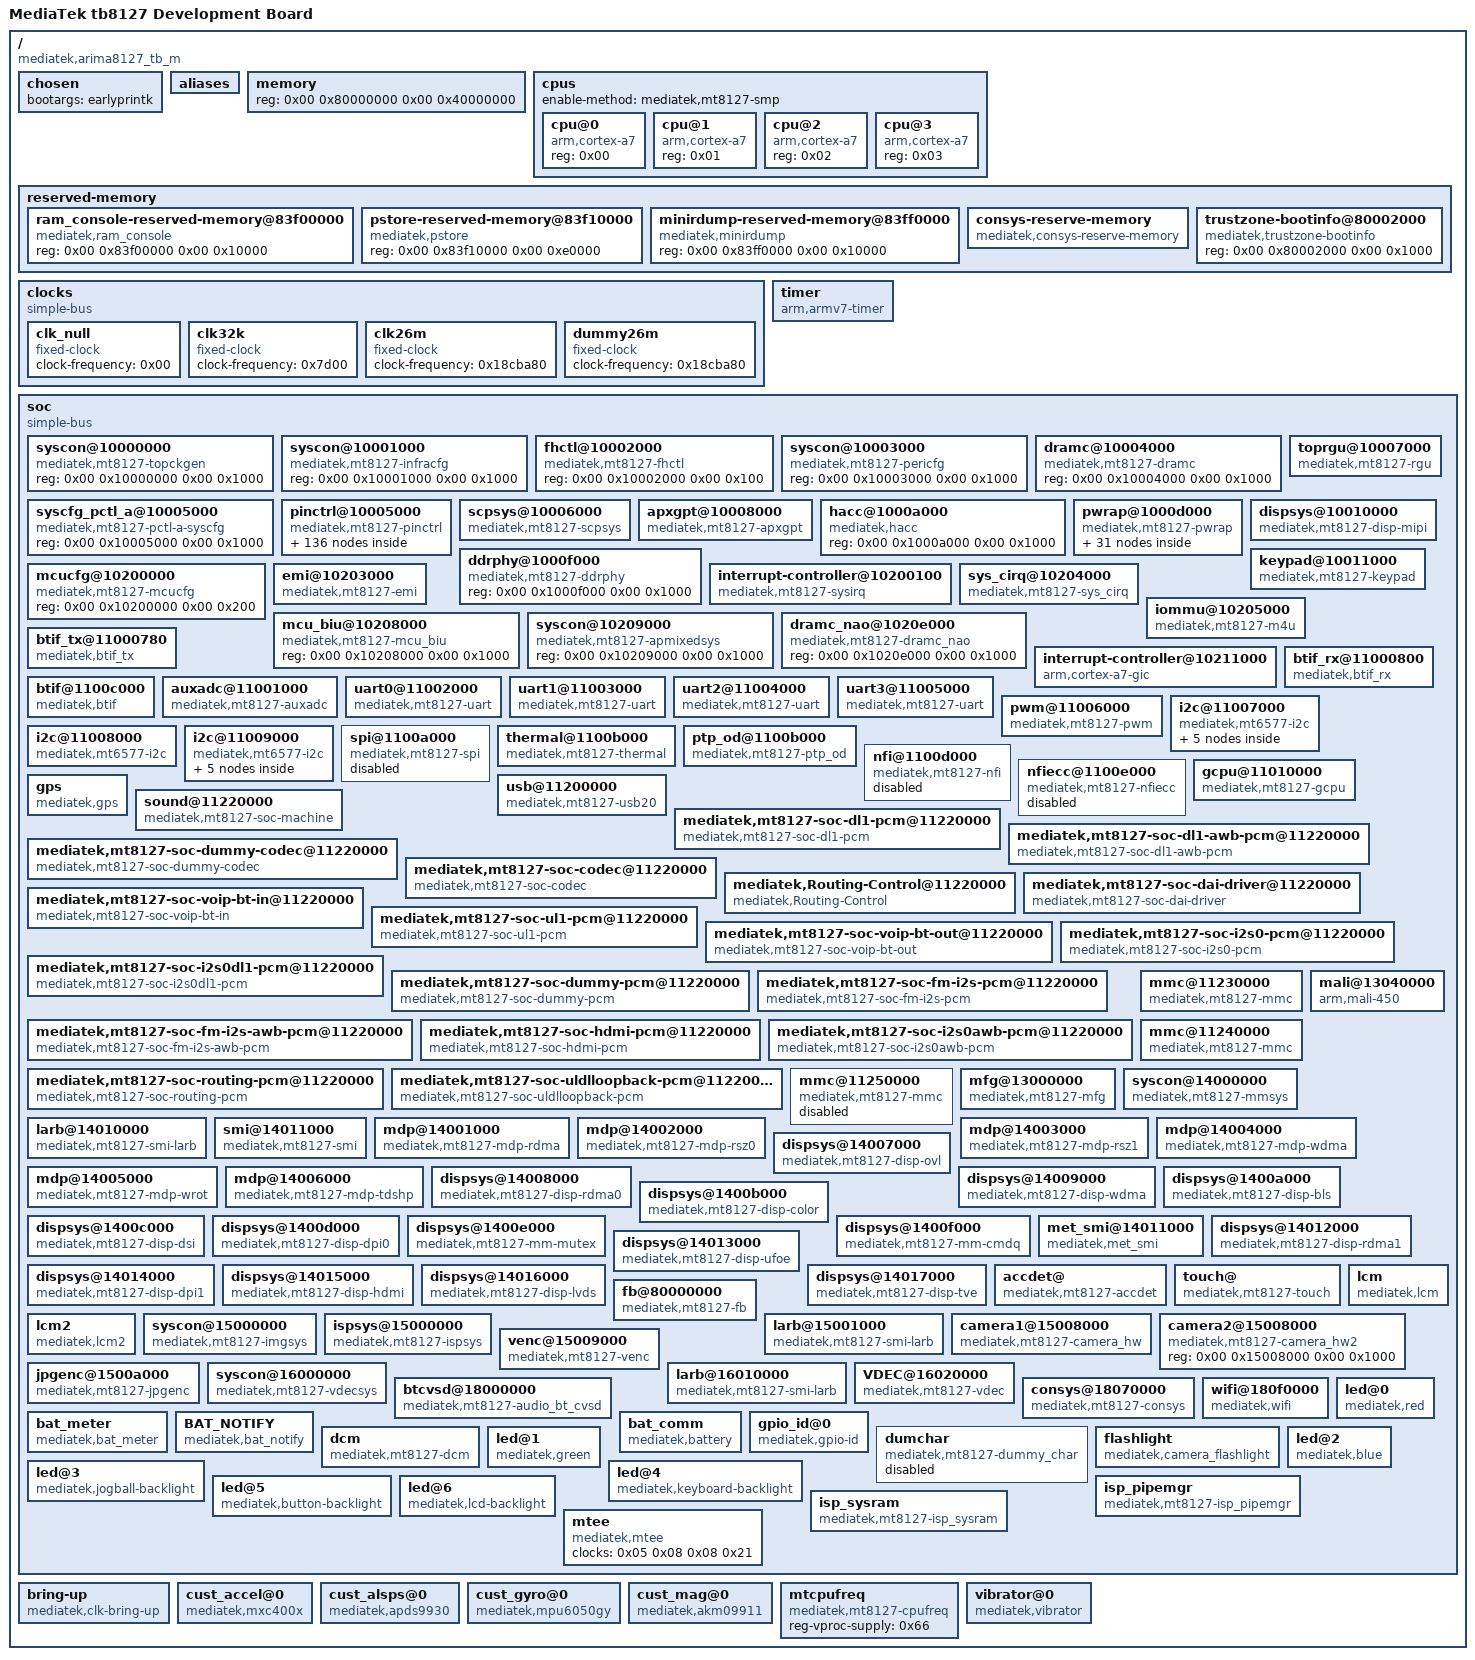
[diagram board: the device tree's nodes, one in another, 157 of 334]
/dts-v1/;

/ {
	#address-cells = <0x02>;
	#size-cells = <0x02>;
	compatible = "mediatek,arima8127_tb_m\0mediatek,mt8127";
	interrupt-parent = <0x01>;
	model = "MediaTek tb8127 Development Board";

	chosen {
		bootargs = "earlyprintk";
	};

	aliases {
	};

	memory {
		device_type = "memory";
		reg = <0x00 0x80000000 0x00 0x40000000>;
	};

	cpus {
		#address-cells = <0x01>;
		#size-cells = <0x00>;
		enable-method = "mediatek,mt8127-smp";

		cpu@0 {
			device_type = "cpu";
			compatible = "arm,cortex-a7";
			reg = <0x00>;
		};

		cpu@1 {
			device_type = "cpu";
			compatible = "arm,cortex-a7";
			reg = <0x01>;
		};

		cpu@2 {
			device_type = "cpu";
			compatible = "arm,cortex-a7";
			reg = <0x02>;
		};

		cpu@3 {
			device_type = "cpu";
			compatible = "arm,cortex-a7";
			reg = <0x03>;
		};
	};

	reserved-memory {
		#address-cells = <0x02>;
		#size-cells = <0x02>;
		ranges;

		ram_console-reserved-memory@83f00000 {
			compatible = "mediatek,ram_console";
			reg = <0x00 0x83f00000 0x00 0x10000>;
		};

		pstore-reserved-memory@83f10000 {
			compatible = "mediatek,pstore";
			reg = <0x00 0x83f10000 0x00 0xe0000>;
		};

		minirdump-reserved-memory@83ff0000 {
			compatible = "mediatek,minirdump";
			reg = <0x00 0x83ff0000 0x00 0x10000>;
		};

		consys-reserve-memory {
			compatible = "mediatek,consys-reserve-memory";
			no-map;
			size = <0x00 0x100000>;
			alignment = <0x00 0x100000>;
		};

		trustzone-bootinfo@80002000 {
			compatible = "mediatek,trustzone-bootinfo";
			reg = <0x00 0x80002000 0x00 0x1000>;
		};
	};

	clocks {
		#address-cells = <0x02>;
		#size-cells = <0x02>;
		compatible = "simple-bus";
		ranges;

		clk_null {
			compatible = "fixed-clock";
			#clock-cells = <0x00>;
			clock-frequency = <0x00>;
			linux,phandle = <0x28>;
			phandle = <0x28>;
		};

		clk32k {
			compatible = "fixed-clock";
			clock-frequency = <0x7d00>;
			#clock-cells = <0x00>;
		};

		clk26m {
			compatible = "fixed-clock";
			clock-frequency = <0x18cba80>;
			#clock-cells = <0x00>;
			linux,phandle = <0x27>;
			phandle = <0x27>;
		};

		dummy26m {
			compatible = "fixed-clock";
			clock-frequency = <0x18cba80>;
			#clock-cells = <0x00>;
		};
	};

	timer {
		compatible = "arm,armv7-timer";
		interrupt-parent = <0x02>;
		interrupts = <0x01 0x0d 0xf04 0x01 0x0e 0xf04 0x01 0x0b 0xf04 0x01 0x0a 0xf04>;
	};

	soc {
		#address-cells = <0x02>;
		#size-cells = <0x02>;
		compatible = "simple-bus";
		ranges;

		syscon@10000000 {
			compatible = "mediatek,mt8127-topckgen\0syscon";
			reg = <0x00 0x10000000 0x00 0x1000>;
			#clock-cells = <0x01>;
			linux,phandle = <0x06>;
			phandle = <0x06>;
		};

		syscon@10001000 {
			#address-cells = <0x01>;
			#size-cells = <0x01>;
			compatible = "mediatek,mt8127-infracfg\0syscon";
			reg = <0x00 0x10001000 0x00 0x1000>;
			#clock-cells = <0x01>;
			#reset-cells = <0x01>;
			linux,phandle = <0x05>;
			phandle = <0x05>;
		};

		fhctl@10002000 {
			compatible = "mediatek,mt8127-fhctl";
			reg = <0x00 0x10002000 0x00 0x100>;
		};

		syscon@10003000 {
			#address-cells = <0x01>;
			#size-cells = <0x01>;
			compatible = "mediatek,mt8127-pericfg\0syscon";
			reg = <0x00 0x10003000 0x00 0x1000>;
			#clock-cells = <0x01>;
			#reset-cells = <0x01>;
			linux,phandle = <0x08>;
			phandle = <0x08>;
		};

		dramc@10004000 {
			compatible = "mediatek,mt8127-dramc";
			reg = <0x00 0x10004000 0x00 0x1000>;
		};

		syscfg_pctl_a@10005000 {
			compatible = "mediatek,mt8127-pctl-a-syscfg\0syscon";
			reg = <0x00 0x10005000 0x00 0x1000>;
			linux,phandle = <0x03>;
			phandle = <0x03>;
		};

		pinctrl@10005000 {
			compatible = "mediatek,mt8127-pinctrl";
			reg = <0x00 0x1000b000 0x00 0x1000>;
			mediatek,pctl-regmap = <0x03>;
			pins-are-numbered;
			gpio-controller;
			#gpio-cells = <0x02>;
			interrupt-controller;
			#interrupt-cells = <0x02>;
			interrupts = <0x00 0x71 0x04 0x00 0x72 0x04>;
			pinctrl-names = "default";
			pinctrl-0 = <0x04>;
			linux,phandle = <0x07>;
			phandle = <0x07>;

			uart0gpiodefault {
				linux,phandle = <0x09>;
				phandle = <0x09>;
			};

			uart0_rx_set {
				linux,phandle = <0x0a>;
				phandle = <0x0a>;

				pins_cmd_dat {
					pinmux = <0x4f01>;
				};
			};

			uart0_rx_clear {
				linux,phandle = <0x0b>;
				phandle = <0x0b>;

				pins_cmd_dat {
					pinmux = <0x4f00>;
					slew-rate = <0x01>;
					output-high;
				};
			};

			uart0_tx_set {
				linux,phandle = <0x0c>;
				phandle = <0x0c>;

				pins_cmd_dat {
					pinmux = <0x5001>;
				};
			};

			uart0_tx_clear {
				linux,phandle = <0x0d>;
				phandle = <0x0d>;

				pins_cmd_dat {
					pinmux = <0x5000>;
					slew-rate = <0x01>;
					output-high;
				};
			};

			uart1gpiodefault {
				linux,phandle = <0x0e>;
				phandle = <0x0e>;
			};

			uart1_rx_set {
				linux,phandle = <0x0f>;
				phandle = <0x0f>;

				pins_cmd_dat {
					pinmux = <0x5101>;
				};
			};

			uart1_rx_clear {
				linux,phandle = <0x10>;
				phandle = <0x10>;

				pins_cmd_dat {
					pinmux = <0x5100>;
					slew-rate = <0x01>;
					output-high;
				};
			};

			uart1_tx_set {
				linux,phandle = <0x11>;
				phandle = <0x11>;

				pins_cmd_dat {
					pinmux = <0x5201>;
				};
			};

			uart1_tx_clear {
				linux,phandle = <0x12>;
				phandle = <0x12>;

				pins_cmd_dat {
					pinmux = <0x5200>;
					slew-rate = <0x01>;
					output-high;
				};
			};

			uart2gpiodefault {
				linux,phandle = <0x13>;
				phandle = <0x13>;
			};

			uart2_rx_set {
				linux,phandle = <0x14>;
				phandle = <0x14>;

				pins_cmd_dat {
					pinmux = <0xe01>;
				};
			};

			uart2_rx_clear {
				linux,phandle = <0x15>;
				phandle = <0x15>;

				pins_cmd_dat {
					pinmux = <0xe00>;
					slew-rate = <0x01>;
					output-high;
				};
			};

			uart2_tx_set {
				linux,phandle = <0x16>;
				phandle = <0x16>;

				pins_cmd_dat {
					pins = <0xf01>;
				};
			};

			uart2_tx_clear {
				linux,phandle = <0x17>;
				phandle = <0x17>;

				pins_cmd_dat {
					pinmux = <0xf00>;
					slew-rate = <0x01>;
					output-high;
				};
			};

			uart3gpiodefault {
				linux,phandle = <0x18>;
				phandle = <0x18>;
			};

			uart3_rx_set {
				linux,phandle = <0x19>;
				phandle = <0x19>;

				pins_cmd_dat {
					pinmux = <0x1001>;
				};
			};

			uart3_rx_clear {
				linux,phandle = <0x1a>;
				phandle = <0x1a>;

				pins_cmd_dat {
					pinmux = <0x1000>;
					slew-rate = <0x01>;
					output-high;
				};
			};

			uart3_tx_set {
				linux,phandle = <0x1b>;
				phandle = <0x1b>;

				pins_cmd_dat {
					pinmux = <0x1101>;
				};
			};

			uart3_tx_clear {
				linux,phandle = <0x1c>;
				phandle = <0x1c>;

				pins_cmd_dat {
					pinmux = <0x1100>;
					slew-rate = <0x01>;
					output-high;
				};
			};

			pinconf_default {
				linux,phandle = <0x04>;
				phandle = <0x04>;
			};

			eint4default {
				linux,phandle = <0x38>;
				phandle = <0x38>;
			};

			eint4 {
				linux,phandle = <0x39>;
				phandle = <0x39>;

				pins_cmd_dat {
					pins = <0x1a00>;
					bias-disable;
				};
			};

			cam0@0 {
				linux,phandle = <0x47>;
				phandle = <0x47>;

				pins_cmd_dat {
					pins = <0x3500>;
					slew-rate = <0x01>;
					output-low;
				};
			};

			cam0@1 {
				linux,phandle = <0x48>;
				phandle = <0x48>;

				pins_cmd_dat {
					pins = <0x3500>;
					slew-rate = <0x01>;
					output-high;
				};
			};

			cam0@2 {
				linux,phandle = <0x49>;
				phandle = <0x49>;

				pins_cmd_dat {
					pins = <0x3800>;
					slew-rate = <0x01>;
					output-low;
				};
			};

			cam0@3 {
				linux,phandle = <0x4a>;
				phandle = <0x4a>;

				pins_cmd_dat {
					pins = <0x3800>;
					slew-rate = <0x01>;
					output-high;
				};
			};

			cam1@0 {
				linux,phandle = <0x4b>;
				phandle = <0x4b>;

				pins_cmd_dat {
					pins = <0x3700>;
					slew-rate = <0x01>;
					output-low;
				};
			};

			cam1@1 {
				linux,phandle = <0x4c>;
				phandle = <0x4c>;

				pins_cmd_dat {
					pins = <0x3700>;
					slew-rate = <0x01>;
					output-high;
				};
			};

			cam1@2 {
				linux,phandle = <0x4d>;
				phandle = <0x4d>;

				pins_cmd_dat {
					pins = <0x3600>;
					slew-rate = <0x01>;
					output-low;
				};
			};

			cam1@3 {
				linux,phandle = <0x4e>;
				phandle = <0x4e>;

				pins_cmd_dat {
					pins = <0x3600>;
					slew-rate = <0x01>;
					output-high;
				};
			};

			camdefault {
				linux,phandle = <0x46>;
				phandle = <0x46>;

				pins_cmd_dat {
					pins = <0x7701 0x7801>;
				};
			};

			cam_mclk_cfg {
				linux,phandle = <0x4f>;
				phandle = <0x4f>;

				pins_cmd_dat {
					pins = <0x7701>;
					slew-rate = <0x01>;
					output-low;
				};
			};

			cam_mclk_gpio {
				linux,phandle = <0x50>;
				phandle = <0x50>;

				pins_cmd_dat {
					pins = <0x7700>;
					slew-rate = <0x01>;
					output-low;
				};
			};

			default {
				linux,phandle = <0x52>;
				phandle = <0x52>;
			};

			eint0default {
				linux,phandle = <0x3b>;
				phandle = <0x3b>;
			};

			eint@0 {
				linux,phandle = <0x3c>;
				phandle = <0x3c>;

				pins_cmd_dat {
					pins = <0x2300>;
					slew-rate = <0x00>;
					bias-enable;
					bias-pull-up = <0x00>;
				};
			};

			eintoutput0 {
				linux,phandle = <0x3d>;
				phandle = <0x3d>;

				pins_cmd_dat {
					pins = <0x2300>;
					slew-rate = <0x00>;
					bias-enable;
					bias-pull-up = <0x00>;
				};
			};

			eintoutput1 {
				linux,phandle = <0x3e>;
				phandle = <0x3e>;

				pins_cmd_dat {
					pins = <0x2300>;
					slew-rate = <0x00>;
					bias-enable;
					bias-pull-up = <0x00>;
				};
			};

			rstoutput0 {
				linux,phandle = <0x3f>;
				phandle = <0x3f>;

				pins_cmd_dat {
					pins = <0x2d00>;
					slew-rate = <0x01>;
					output-low;
				};
			};

			rstoutput1 {
				linux,phandle = <0x40>;
				phandle = <0x40>;

				pins_cmd_dat {
					pins = <0x2d00>;
					slew-rate = <0x01>;
					output-high;
				};
			};

			enable_high {
				linux,phandle = <0x64>;
				phandle = <0x64>;

				pins_cmd_dat {
					pins = <0x7500>;
					slew-rate = <0x01>;
					output-high;
				};
			};

			enable_low {
				linux,phandle = <0x65>;
				phandle = <0x65>;

				pins_cmd_dat {
					pins = <0x7500>;
					slew-rate = <0x01>;
					output-low;
				};
			};

			drvvbus_init {
				linux,phandle = <0x24>;
				phandle = <0x24>;

				pins_cmd_dat {
					pins = <0x2302>;
					slew-rate = <0x01>;
					bias-pull-up = <0x00>;
				};
			};

			drvvbus_low {
				linux,phandle = <0x25>;
				phandle = <0x25>;

				pins_cmd_dat {
					pins = <0x2302>;
					slew-rate = <0x01>;
					output-low;
				};
			};

			drvvbus_high {
				linux,phandle = <0x26>;
				phandle = <0x26>;

				pins_cmd_dat {
					pins = <0x2302>;
					slew-rate = <0x01>;
					output-high;
				};
			};

			iddig_irq_init {
				linux,phandle = <0x23>;
				phandle = <0x23>;

				pins_cmd_dat {
					pins = <0x2600>;
					slew-rate = <0x00>;
					bias-pull-up = <0x00>;
				};
			};

			gpslna@0 {
				linux,phandle = <0x53>;
				phandle = <0x53>;

				pins_cmd_dat {
					pinmux = <0x7600>;
					slew-rate = <0x00>;
					bias-disable;
					output-low;
				};
			};

			gpslna@1 {
				linux,phandle = <0x54>;
				phandle = <0x54>;

				pins_cmd_dat {
					pinmux = <0x7600>;
					slew-rate = <0x01>;
					output-high;
				};
			};

			gpslna@2 {
				linux,phandle = <0x55>;
				phandle = <0x55>;

				pins_cmd_dat {
					pinmux = <0x7600>;
					slew-rate = <0x01>;
					output-low;
				};
			};

			hdmi_pins_default {
				linux,phandle = <0x36>;
				phandle = <0x36>;

				pins_cmd_dat {
					pinmux = <0x1b00>;
					slew-rate = <0x01>;
					bias-pull-up;
					output-high;
				};
			};

			hdmi_pins_hpd {
				linux,phandle = <0x37>;
				phandle = <0x37>;

				pins_cmd_dat {
					pinmux = <0x8b01>;
					slew-rate = <0x00>;
					bias-pull-down;
				};
			};

			i2c0@0 {
				linux,phandle = <0x1d>;
				phandle = <0x1d>;

				pins1 {
					pinmux = <0x4b01 0x4c01>;
					bias-disable;
				};
			};

			i2c1@0 {
				linux,phandle = <0x1e>;
				phandle = <0x1e>;

				pins1 {
					pinmux = <0x3901 0x3a01>;
					bias-disable;
				};
			};

			i2c2@0 {
				linux,phandle = <0x1f>;
				phandle = <0x1f>;

				pins1 {
					pinmux = <0x4d01 0x4e01>;
					bias-disable;
				};
			};

			mmc0default {
				linux,phandle = <0x29>;
				phandle = <0x29>;

				pins_cmd_dat {
					pinmux = <0x8901 0x8801 0x8701 0x8601 0x8201 0x8101 0x8001 0x7f01 0x8401>;
					input-enable;
					bias-pull-up;
				};

				pins_clk {
					pinmux = <0x8501>;
					bias-pull-down;
				};

				pins_rst {
					pinmux = <0x8301>;
					bias-pull-up;
				};
			};

			mmc0@0 {
				linux,phandle = <0x2a>;
				phandle = <0x2a>;

				pins_cmd_dat {
					pinmux = <0x8901 0x8801 0x8701 0x8601 0x8201 0x8101 0x8001 0x7f01 0x8401>;
					input-enable;
					drive-strength = <0x0a>;
					bias-pull-up = <0x65>;
				};

				pins_clk {
					pinmux = <0x8501>;
					drive-strength = <0x0a>;
					bias-pull-down = <0x66>;
				};

				pins_rst {
					pinmux = <0x8301>;
					bias-pull-up;
				};
			};

			mmc1default {
				linux,phandle = <0x2d>;
				phandle = <0x2d>;

				pins_cmd_dat {
					pinmux = <0x7b01 0x7c01 0x7d01 0x7e01 0x7901>;
					input-enable;
					drive-strength = <0x04>;
					bias-pull-up = <0x66>;
				};

				pins_clk {
					pinmux = <0x7a01>;
					bias-pull-down;
					drive-strength = <0x04>;
				};

				pins_insert {
					pinmux = <0x1800>;
					bias-pull-up;
				};
			};

			mmc1@0 {
				linux,phandle = <0x2e>;
				phandle = <0x2e>;

				pins_cmd_dat {
					pinmux = <0x7b01 0x7c01 0x7d01 0x7e01 0x7901>;
					input-enable;
					drive-strength = <0x08>;
					bias-pull-up = <0x66>;
				};

				pins_clk {
					pinmux = <0x7a01>;
					drive-strength = <0x08>;
					bias-pull-down = <0x66>;
				};
			};

			gpio_set_33 {
				linux,phandle = <0x61>;
				phandle = <0x61>;

				pins_cmd_dat {
					pins = <0x2100>;
					slew-rate = <0x00>;
					bias-disable;
				};
			};

			gpio_set_37 {
				linux,phandle = <0x62>;
				phandle = <0x62>;

				pins_cmd_dat {
					pins = <0x2500>;
					slew-rate = <0x00>;
					bias-disable;
				};
			};

			gpio_set_21 {
				linux,phandle = <0x63>;
				phandle = <0x63>;

				pins_cmd_dat {
					pins = <0x1500>;
					slew-rate = <0x00>;
					bias-disable;
				};
			};

			bq24157s_0@0 {
				linux,phandle = <0x5b>;
				phandle = <0x5b>;

				pins_cmd_dat {
					pins = <0x1600>;
					slew-rate = <0x01>;
					output-low;
				};
			};

			bq24157s_1@1 {
				linux,phandle = <0x5c>;
				phandle = <0x5c>;

				pins_cmd_dat {
					pins = <0x1600>;
					slew-rate = <0x01>;
					output-high;
				};
			};

			bq24157s_2@2 {
				linux,phandle = <0x5d>;
				phandle = <0x5d>;

				pins_cmd_dat {
					pins = <0x1700>;
					slew-rate = <0x00>;
					bias-enable;
					bias-pull-up = <0x00>;
				};
			};

			bq24157s_3@3 {
				linux,phandle = <0x5e>;
				phandle = <0x5e>;

				pins_cmd_dat {
					pins = <0x1700>;
					slew-rate = <0x00>;
					bias-enable;
					bias-pull-up = <0x00>;
				};
			};

			bq24157s_4@4 {
				linux,phandle = <0x5f>;
				phandle = <0x5f>;

				pins_cmd_dat {
					pins = <0x1900>;
					slew-rate = <0x00>;
					bias-enable;
					bias-pull-up = <0x00>;
				};
			};

			bq24157s_5@5 {
				linux,phandle = <0x60>;
				phandle = <0x60>;

				pins_cmd_dat {
					pins = <0x1900>;
					slew-rate = <0x00>;
					bias-enable;
					bias-pull-up = <0x00>;
				};
			};

			chargerdefault {
				linux,phandle = <0x5a>;
				phandle = <0x5a>;
			};
		};

		scpsys@10006000 {
			compatible = "mediatek,mt8127-scpsys\0syscon";
			#power-domain-cells = <0x01>;
			reg = <0x00 0x10006000 0x00 0x1000>;
			interrupts = <0x00 0x75 0x08 0x00 0x76 0x08>;
			infracfg = <0x05>;
			clocks = <0x06 0x41>;
			clock-names = "mm";
			linux,phandle = <0x31>;
			phandle = <0x31>;
		};

		toprgu@10007000 {
			compatible = "mediatek,mt8127-rgu";
			reg = <0x00 0x10007000 0x00 0x1000>;
			interrupts = <0x00 0x58 0x02>;
			#reset-cells = <0x01>;
			linux,phandle = <0x51>;
			phandle = <0x51>;
		};

		apxgpt@10008000 {
			compatible = "mediatek,mt8127-apxgpt";
			reg = <0x00 0x10008000 0x00 0x1000>;
			interrupts = <0x00 0x70 0x08>;
			clocks = <0x05 0x0f 0x06 0x5b>;
			clock-names = "clk13m\0rtc_sel";
		};

		hacc@1000a000 {
			compatible = "mediatek,hacc";
			reg = <0x00 0x1000a000 0x00 0x1000>;
		};

		pwrap@1000d000 {
			compatible = "mediatek,mt8127-pwrap";
			reg = <0x00 0x1000d000 0x00 0x1000>;
			reg-names = "pwrap";
			interrupts = <0x00 0x73 0x04>;
			clocks = <0x05 0x0d 0x05 0x0e>;
			clock-names = "spi\0wrap";

			mt6323 {
				compatible = "mediatek,mt6323";
				#address-cells = <0x01>;
				#size-cells = <0x01>;

				pmicmt6323 {
					compatible = "mediatek,mt6323-pmic";
					interrupt-parent = <0x07>;
					interrupts = <0x18 0x04>;
				};

				mt6323regulator {
					compatible = "mediatek,mt6323-regulator";

					buck_vproc {
						regulator-name = "vproc";
						regulator-min-microvolt = <0xaae60>;
						regulator-max-microvolt = <0x149970>;
						regulator-ramp-delay = <0x30d4>;
						regulator-always-on;
						regulator-boot-on;
						linux,phandle = <0x66>;
						phandle = <0x66>;
					};

					buck_vsys {
						regulator-name = "vsys";
						regulator-min-microvolt = <0x155cc0>;
						regulator-max-microvolt = <0x2d95ec>;
						regulator-ramp-delay = <0x61a8>;
						regulator-always-on;
						regulator-boot-on;
					};

					buck_vpa {
						regulator-name = "vpa";
						regulator-min-microvolt = <0x7a120>;
						regulator-max-microvolt = <0x37b1d0>;
					};

					ldo_vtcxo {
						regulator-name = "vtcxo";
						regulator-min-microvolt = <0x2ab980>;
						regulator-max-microvolt = <0x2ab980>;
						regulator-enable-ramp-delay = <0x5a>;
						regulator-always-on;
						regulator-boot-on;
					};

					ldo_vcn28 {
						regulator-name = "vcn28";
						regulator-min-microvolt = <0x2ab980>;
						regulator-max-microvolt = <0x2ab980>;
						regulator-enable-ramp-delay = <0xb9>;
						linux,phandle = <0x57>;
						phandle = <0x57>;
					};

					ldo_vcn33_bt {
						regulator-name = "vcn33_bt";
						regulator-min-microvolt = <0x325aa0>;
						regulator-max-microvolt = <0x36ee80>;
						regulator-enable-ramp-delay = <0xb9>;
						linux,phandle = <0x58>;
						phandle = <0x58>;
					};

					ldo_vcn33_wifi {
						regulator-name = "vcn33_wifi";
						regulator-min-microvolt = <0x325aa0>;
						regulator-max-microvolt = <0x36ee80>;
						regulator-enable-ramp-delay = <0xb9>;
						linux,phandle = <0x59>;
						phandle = <0x59>;
					};

					ldo_va {
						regulator-name = "va";
						regulator-min-microvolt = <0x2ab980>;
						regulator-max-microvolt = <0x2ab980>;
						regulator-enable-ramp-delay = <0xd8>;
						regulator-always-on;
						regulator-boot-on;
					};

					ldo_vcama {
						regulator-name = "vcama";
						regulator-min-microvolt = <0x16e360>;
						regulator-max-microvolt = <0x2ab980>;
						regulator-enable-ramp-delay = <0xd8>;
						linux,phandle = <0x42>;
						phandle = <0x42>;
					};

					ldo_vio28 {
						regulator-name = "vio28";
						regulator-min-microvolt = <0x2ab980>;
						regulator-max-microvolt = <0x2ab980>;
						regulator-enable-ramp-delay = <0xd8>;
						regulator-always-on;
						regulator-boot-on;
					};

					ldo_vusb {
						regulator-name = "vusb";
						regulator-min-microvolt = <0x325aa0>;
						regulator-max-microvolt = <0x325aa0>;
						regulator-enable-ramp-delay = <0xd8>;
						regulator-boot-on;
						linux,phandle = <0x22>;
						phandle = <0x22>;
					};

					ldo_vmc {
						regulator-name = "vmc";
						regulator-min-microvolt = <0x1b7740>;
						regulator-max-microvolt = <0x325aa0>;
						regulator-enable-ramp-delay = <0x24>;
						regulator-boot-on;
						linux,phandle = <0x30>;
						phandle = <0x30>;
					};

					ldo_vmch {
						regulator-name = "vmch";
						regulator-min-microvolt = <0x2dc6c0>;
						regulator-max-microvolt = <0x325aa0>;
						regulator-enable-ramp-delay = <0x24>;
						regulator-always-on;
						regulator-boot-on;
						linux,phandle = <0x2f>;
						phandle = <0x2f>;
					};

					ldo_vemc3v3 {
						regulator-name = "vemc3v3";
						regulator-min-microvolt = <0x2dc6c0>;
						regulator-max-microvolt = <0x325aa0>;
						regulator-enable-ramp-delay = <0x24>;
						regulator-boot-on;
						linux,phandle = <0x2b>;
						phandle = <0x2b>;
					};

					ldo_vgp1 {
						regulator-name = "vgp1";
						regulator-min-microvolt = <0x124f80>;
						regulator-max-microvolt = <0x325aa0>;
						regulator-enable-ramp-delay = <0xd8>;
					};

					ldo_vgp2 {
						regulator-name = "vgp2";
						regulator-min-microvolt = <0x124f80>;
						regulator-max-microvolt = <0x2dc6c0>;
						regulator-enable-ramp-delay = <0xd8>;
						linux,phandle = <0x3a>;
						phandle = <0x3a>;
					};

					ldo_vgp3 {
						regulator-name = "vgp3";
						regulator-min-microvolt = <0x124f80>;
						regulator-max-microvolt = <0x1b7740>;
						regulator-enable-ramp-delay = <0xd8>;
						linux,phandle = <0x41>;
						phandle = <0x41>;
					};

					ldo_vcn18 {
						regulator-name = "vcn18";
						regulator-min-microvolt = <0x1b7740>;
						regulator-max-microvolt = <0x1b7740>;
						regulator-enable-ramp-delay = <0xd8>;
						linux,phandle = <0x56>;
						phandle = <0x56>;
					};

					ldo_vsim1 {
						regulator-name = "vsim1";
						regulator-min-microvolt = <0x1b7740>;
						regulator-max-microvolt = <0x2dc6c0>;
						regulator-enable-ramp-delay = <0xd8>;
					};

					ldo_vsim2 {
						regulator-name = "vsim2";
						regulator-min-microvolt = <0x1b7740>;
						regulator-max-microvolt = <0x2dc6c0>;
						regulator-enable-ramp-delay = <0xd8>;
					};

					ldo_vrtc {
						regulator-name = "vrtc";
						regulator-min-microvolt = <0x2ab980>;
						regulator-max-microvolt = <0x2ab980>;
						regulator-always-on;
						regulator-boot-on;
					};

					ldo_vcamaf {
						regulator-name = "vcamaf";
						regulator-min-microvolt = <0x124f80>;
						regulator-max-microvolt = <0x325aa0>;
						regulator-enable-ramp-delay = <0xd8>;
						linux,phandle = <0x45>;
						phandle = <0x45>;
					};

					ldo_vibr {
						regulator-name = "vibr";
						regulator-min-microvolt = <0x124f80>;
						regulator-max-microvolt = <0x325aa0>;
						regulator-enable-ramp-delay = <0x24>;
					};

					ldo_vrf18 {
						regulator-name = "vrf18";
						regulator-min-microvolt = <0x1bd8e8>;
						regulator-max-microvolt = <0x1bd8e8>;
						regulator-enable-ramp-delay = <0xbb>;
					};

					ldo_vm {
						regulator-name = "vm";
						regulator-min-microvolt = <0x124f80>;
						regulator-max-microvolt = <0x1b7740>;
						regulator-enable-ramp-delay = <0xd8>;
						regulator-always-on;
						regulator-boot-on;
					};

					ldo_vio18 {
						regulator-name = "vio18";
						regulator-min-microvolt = <0x1b7740>;
						regulator-max-microvolt = <0x1b7740>;
						regulator-enable-ramp-delay = <0xd8>;
						regulator-always-on;
						regulator-boot-on;
						linux,phandle = <0x2c>;
						phandle = <0x2c>;
					};

					ldo_vcamd {
						regulator-name = "vcamd";
						regulator-min-microvolt = <0x124f80>;
						regulator-max-microvolt = <0x1b7740>;
						regulator-enable-ramp-delay = <0xd8>;
						linux,phandle = <0x43>;
						phandle = <0x43>;
					};

					ldo_vcamio {
						regulator-name = "vcamio";
						regulator-min-microvolt = <0x1b7740>;
						regulator-max-microvolt = <0x1b7740>;
						regulator-enable-ramp-delay = <0xd8>;
						linux,phandle = <0x44>;
						phandle = <0x44>;
					};
				};
			};
		};

		ddrphy@1000f000 {
			compatible = "mediatek,mt8127-ddrphy";
			reg = <0x00 0x1000f000 0x00 0x1000>;
		};

		dispsys@10010000 {
			compatible = "mediatek,mt8127-disp-mipi";
			reg = <0x00 0x10010000 0x00 0x1000>;
			clocks = <0x06 0x30 0x06 0x31 0x06 0x32>;
			clock-names = "clk_mipipll\0clk_mipipll_d2\0clk_mipipll_d4";
		};

		keypad@10011000 {
			compatible = "mediatek,mt8127-keypad";
			reg = <0x00 0x10011000 0x00 0x1000>;
			interrupts = <0x00 0x74 0x02>;
			clocks = <0x05 0x0a>;
			clock-names = "kpd-clk";
			status = "okay";
			mediatek,kpd-key-debounce = <0x400>;
			mediatek,kpd-sw-pwrkey = <0x74>;
			mediatek,kpd-hw-pwrkey = <0x08>;
			mediatek,kpd-sw-rstkey = <0x72>;
			mediatek,kpd-hw-rstkey = <0x11>;
			mediatek,kpd-use-extend-type = <0x00>;
			mediatek,kpd-hw-map-num = <0x48>;
			mediatek,kpd-hw-init-map = <0x73 0x72 0x00 0x00 0x00 0x00 0x00 0x00 0x00 0x00 0x00 0x00 0x00 0x00 0x00 0x00 0x00 0x00 0x00 0x00 0x00 0x00 0x00 0x00 0x00 0x00 0x00 0x00 0x00 0x00 0x00 0x00 0x00 0x00 0x00 0x00 0x00 0x00 0x00 0x00 0x00 0x00 0x00 0x00 0x00 0x00 0x00 0x00 0x00 0x00 0x00 0x00 0x00 0x00 0x00 0x00 0x00 0x00 0x00 0x00 0x00 0x00 0x00 0x00 0x00 0x00 0x00 0x00 0x00 0x00 0x00 0x00>;
			mediatek,kpd-pwrkey-eint-gpio = <0x00>;
			mediatek,kpd-pwkey-gpio-din = <0x00>;
			mediatek,kpd-hw-dl-key0 = <0x00>;
			mediatek,kpd-hw-dl-key1 = <0x01>;
			mediatek,kpd-hw-dl-key2 = <0x08>;
			mediatek,kpd-hw-recovery-key = <0x00>;
			mediatek,kpd-hw-factory-key = <0x01>;
		};

		mcucfg@10200000 {
			compatible = "mediatek,mt8127-mcucfg";
			reg = <0x00 0x10200000 0x00 0x200>;
		};

		interrupt-controller@10200100 {
			compatible = "mediatek,mt8127-sysirq\0mediatek,mt6577-sysirq";
			interrupt-controller;
			#interrupt-cells = <0x03>;
			interrupt-parent = <0x02>;
			reg = <0x00 0x10200100 0x00 0x1c>;
			linux,phandle = <0x01>;
			phandle = <0x01>;
		};

		emi@10203000 {
			compatible = "mediatek,mt8127-emi\0mediatek,emi";
			reg = <0x00 0x10203000 0x00 0x1000>;
			interrupts = <0x00 0x5e 0x04>;
		};

		sys_cirq@10204000 {
			compatible = "mediatek,mt8127-sys_cirq\0mediatek,mt6735-sys_cirq";
			reg = <0x00 0x10204000 0x00 0x1000>;
			interrupts = <0x00 0xbb 0x08>;
			mediatek,cirq_num = <0xa8>;
			mediatek,spi_start_offset = <0x40>;
		};

		iommu@10205000 {
			compatible = "mediatek,mt8127-m4u";
			reg = <0x00 0x10205000 0x00 0x1000 0x00 0x1000c000 0x00 0x1000>;
			interrupts = <0x00 0x6a 0x08>;
			clocks = <0x05 0x06 0x05 0x02>;
			clock-names = "bclk\0async";
			#iommu-cells = <0x01>;
		};

		mcu_biu@10208000 {
			compatible = "mediatek,mt8127-mcu_biu";
			reg = <0x00 0x10208000 0x00 0x1000>;
		};

		syscon@10209000 {
			compatible = "mediatek,mt8127-apmixedsys";
			reg = <0x00 0x10209000 0x00 0x1000>;
			#clock-cells = <0x01>;
			linux,phandle = <0x21>;
			phandle = <0x21>;
		};

		dramc_nao@1020e000 {
			compatible = "mediatek,mt8127-dramc_nao";
			reg = <0x00 0x1020e000 0x00 0x1000>;
		};

		interrupt-controller@10211000 {
			compatible = "arm,cortex-a7-gic";
			interrupt-controller;
			#interrupt-cells = <0x03>;
			interrupt-parent = <0x02>;
			reg = <0x00 0x10211000 0x00 0x1000 0x00 0x10212000 0x00 0x1000 0x00 0x10214000 0x00 0x2000 0x00 0x10216000 0x00 0x2000>;
			linux,phandle = <0x02>;
			phandle = <0x02>;
		};

		btif_tx@11000780 {
			compatible = "mediatek,btif_tx";
			reg = <0x00 0x11000780 0x00 0x80>;
			interrupts = <0x00 0x47 0x08>;
		};

		btif_rx@11000800 {
			compatible = "mediatek,btif_rx";
			reg = <0x00 0x11000800 0x00 0x80>;
			interrupts = <0x00 0x48 0x08>;
		};

		btif@1100c000 {
			compatible = "mediatek,btif";
			reg = <0x00 0x1100c000 0x00 0x1000>;
			interrupts = <0x00 0x32 0x08>;
			clocks = <0x08 0x16 0x08 0x0d>;
			clock-names = "btifc\0apdmac";
		};

		auxadc@11001000 {
			compatible = "mediatek,mt8127-auxadc\0mediatek,mt6735-auxadc";
			reg = <0x00 0x11001000 0x00 0x1000>;
			interrupts = <0x00 0x24 0x02>;
			clocks = <0x08 0x1b>;
			clock-names = "auxadc-main";
			status = "okay";
			linux,phandle = <0x20>;
			phandle = <0x20>;
		};

		uart0@11002000 {
			cell-index = <0x00>;
			compatible = "mediatek,mt8127-uart";
			reg = <0x00 0x11002000 0x00 0x1000 0x00 0x11000380 0x00 0x1000 0x00 0x11000400 0x00 0x80>;
			interrupts = <0x00 0x33 0x08 0x00 0x5f 0x08 0x00 0x60 0x08>;
			clock-frequency = <0x18cba80>;
			clock-div = <0x01>;
			clocks = <0x08 0x12 0x08 0x0d>;
			clock-names = "uart0-main\0uart-apdma";
			pinctrl-names = "uart0_gpio_default\0uart0_rx_set\0uart0_rx_clear\0uart0_tx_set\0uart0_tx_clear";
			pinctrl-0 = <0x09>;
			pinctrl-1 = <0x0a>;
			pinctrl-2 = <0x0b>;
			pinctrl-3 = <0x0c>;
			pinctrl-4 = <0x0d>;
			rx_gpios = <0x07 0x4f 0x00>;
			tx_gpios = <0x07 0x50 0x00>;
			status = "okay";
		};

		uart1@11003000 {
			cell-index = <0x01>;
			compatible = "mediatek,mt8127-uart";
			reg = <0x00 0x11003000 0x00 0x1000 0x00 0x11000480 0x00 0x80 0x00 0x11000500 0x00 0x80>;
			interrupts = <0x00 0x34 0x08 0x00 0x61 0x08 0x00 0x62 0x08>;
			clock-frequency = <0x18cba80>;
			clock-div = <0x01>;
			clocks = <0x08 0x13>;
			clock-names = "uart1-main";
			pinctrl-names = "uart1_gpio_default\0uart1_rx_set\0uart1_rx_clear\0uart1_tx_set\0uart1_tx_clear";
			pinctrl-0 = <0x0e>;
			pinctrl-1 = <0x0f>;
			pinctrl-2 = <0x10>;
			pinctrl-3 = <0x11>;
			pinctrl-4 = <0x12>;
			rx_gpios = <0x07 0x51 0x00>;
			tx_gpios = <0x07 0x52 0x00>;
			status = "okay";
		};

		uart2@11004000 {
			cell-index = <0x02>;
			compatible = "mediatek,mt8127-uart";
			reg = <0x00 0x11004000 0x00 0x1000 0x00 0x11000580 0x00 0x80 0x00 0x11000600 0x00 0x80>;
			interrupts = <0x00 0x35 0x08 0x00 0x63 0x08 0x00 0x64 0x08>;
			clock-frequency = <0x18cba80>;
			clock-div = <0x01>;
			clocks = <0x08 0x14>;
			clock-names = "uart2-main";
			pinctrl-names = "uart2_gpio_default\0uart2_rx_set\0uart2_rx_clear\0uart2_tx_set\0uart2_tx_clear";
			pinctrl-0 = <0x13>;
			pinctrl-1 = <0x14>;
			pinctrl-2 = <0x15>;
			pinctrl-3 = <0x16>;
			pinctrl-4 = <0x17>;
			rx_gpios = <0x07 0x0e 0x00>;
			tx_gpios = <0x07 0x0f 0x00>;
			status = "okay";
		};

		uart3@11005000 {
			cell-index = <0x03>;
			compatible = "mediatek,mt8127-uart";
			reg = <0x00 0x11005000 0x00 0x1000 0x00 0x11000680 0x00 0x80 0x00 0x11000700 0x00 0x80>;
			interrupts = <0x00 0x36 0x08 0x00 0x65 0x08 0x00 0x66 0x08>;
			clock-frequency = <0x18cba80>;
			clock-div = <0x01>;
			clocks = <0x08 0x15>;
			clock-names = "uart3-main";
			pinctrl-names = "uart3_gpio_default\0uart3_rx_set\0uart3_rx_clear\0uart3_tx_set\0uart3_tx_clear";
			pinctrl-0 = <0x18>;
			pinctrl-1 = <0x19>;
			pinctrl-2 = <0x1a>;
			pinctrl-3 = <0x1b>;
			pinctrl-4 = <0x1c>;
			rx_gpios = <0x07 0x10 0x00>;
			tx_gpios = <0x07 0x11 0x00>;
			status = "okay";
		};

		pwm@11006000 {
			compatible = "mediatek,mt8127-pwm";
			reg = <0x00 0x11006000 0x00 0x1000>;
			interrupts = <0x00 0x4d 0x08>;
			clocks = <0x08 0x0a 0x08 0x03 0x08 0x04 0x08 0x05 0x08 0x06 0x08 0x07>;
			clock-names = "PWM-main\0PWM1-main\0PWM2-main\0PWM3-main\0PWM4-main\0PWM5-main";
		};

		i2c@11007000 {
			compatible = "mediatek,mt6577-i2c";
			reg = <0x00 0x11007000 0x00 0x70 0x00 0x11000200 0x00 0x80>;
			interrupts = <0x00 0x2c 0x08>;
			clock-div = <0x10>;
			clocks = <0x08 0x17 0x08 0x0d>;
			clock-names = "main\0dma";
			#address-cells = <0x01>;
			#size-cells = <0x00>;
			status = "okay";
			pinctrl-names = "default";
			pinctrl-0 = <0x1d>;

			camera_main_af@0c {
				compatible = "mediatek,camera_main_af";
				reg = <0x0c>;
			};

			kd_camera_hw1@30 {
				compatible = "mediatek,camera_main";
				reg = <0x30>;
			};

			cap_touch@15 {
				compatible = "mediatek,cap_touch";
				reg = <0x15>;
			};

			strobe_main@63 {
				compatible = "mediatek,strobe_main";
				reg = <0x63>;
			};

			backlight_led@36 {
				compatible = "mediatek,backlight_led";
				reg = <0x36>;
			};
		};

		i2c@11008000 {
			compatible = "mediatek,mt6577-i2c";
			reg = <0x00 0x11008000 0x00 0x70 0x00 0x11000280 0x00 0x80>;
			interrupts = <0x00 0x2d 0x08>;
			clock-div = <0x10>;
			clocks = <0x08 0x18 0x08 0x0d>;
			clock-names = "main\0dma";
			#address-cells = <0x01>;
			#size-cells = <0x00>;
			status = "okay";
			pinctrl-names = "default";
			pinctrl-0 = <0x1e>;
		};

		i2c@11009000 {
			compatible = "mediatek,mt6577-i2c";
			reg = <0x00 0x11009000 0x00 0x70 0x00 0x11000300 0x00 0x80>;
			interrupts = <0x00 0x2e 0x08>;
			clock-div = <0x10>;
			clocks = <0x08 0x19 0x08 0x0d>;
			clock-names = "main\0dma";
			#address-cells = <0x01>;
			#size-cells = <0x00>;
			status = "okay";
			pinctrl-names = "default";
			pinctrl-0 = <0x1f>;

			msensor@c {
				compatible = "mediatek,msensor";
				reg = <0x0c>;
				status = "okay";
			};

			alsps@39 {
				compatible = "mediatek,alsps";
				reg = <0x39>;
				interrupt-parent = <0x07>;
				interrupts = <0x08 0x08>;
				int-gpio = <0x07 0x1e 0x00>;
				status = "okay";
			};

			gsensor@15 {
				compatible = "mediatek,gsensor";
				reg = <0x15>;
				status = "okay";
			};

			gyro@69 {
				compatible = "mediatek,gyro";
				reg = <0x69>;
				status = "okay";
			};

			bq24157@6a {
				compatible = "ti,bq24157";
				reg = <0x6a>;
			};
		};

		spi@1100a000 {
			compatible = "mediatek,mt8127-spi";
			#address-cells = <0x01>;
			#size-cells = <0x00>;
			reg = <0x00 0x1100a000 0x00 0x1000>;
			interrupts = <0x00 0x4e 0x08>;
			clocks = <0x06 0x14 0x06 0x4b 0x08 0x1c>;
			clock-names = "parent-clk\0sel-clk\0spi-clk";
			status = "disabled";
		};

		thermal@1100b000 {
			compatible = "mediatek,mt8127-thermal";
			reg = <0x00 0x1100b000 0x00 0x1000>;
			interrupts = <0x00 0x46 0x08>;
			clocks = <0x08 0x02 0x08 0x1b>;
			clock-names = "therm\0auxadc";
			auxadc = <0x20>;
			apmixedsys = <0x21>;
			pericfg = <0x08>;
		};

		ptp_od@1100b000 {
			compatible = "mediatek,mt8127-ptp_od";
			reg = <0x00 0x1100b000 0x00 0x1000>;
			interrupts = <0x00 0x55 0x08>;
			clocks = <0x08 0x02>;
			clock-names = "ptp_peri_therm";
		};

		nfi@1100d000 {
			compatible = "mediatek,mt8127-nfi";
			reg = <0x00 0x1100d000 0x00 0x1000>;
			interrupts = <0x00 0x60 0x08>;
			clocks = <0x08 0x01 0x08 0x22 0x08 0x23>;
			clock-names = "nfi_ck\0nfi_ecc_ck\0nfi_pad_ck";
			status = "disabled";
		};

		nfiecc@1100e000 {
			compatible = "mediatek,mt8127-nfiecc";
			reg = <0x00 0x1100e000 0x00 0x1000>;
			interrupts = <0x00 0x5f 0x08>;
			status = "disabled";
		};

		gcpu@11010000 {
			compatible = "mediatek,mt8127-gcpu";
			reg = <0x00 0x11010000 0x00 0x1000>;
			clocks = <0x08 0x21>;
			clock-names = "main";
		};

		gps {
			compatible = "mediatek,gps";
		};

		usb@11200000 {
			compatible = "mediatek,mt8127-usb20";
			reg = <0x00 0x11200000 0x00 0x10000 0x00 0x11210000 0x00 0x10000>;
			interrupts = <0x00 0x20 0x08>;
			mode = <0x02>;
			multipoint = <0x01>;
			dyn_fifo = <0x01>;
			soft_con = <0x01>;
			dma = <0x01>;
			num_eps = <0x10>;
			dma_channels = <0x08>;
			iddig_gpio = <0x07 0x26 0x00>;
			drvvbus_gpio = <0x07 0x23 0x00>;
			clocks = <0x08 0x0b 0x08 0x1e 0x08 0x20>;
			clock-names = "usb0_main\0usb0_mcu\0usb_slv";
			vusb-supply = <0x22>;
			pinctrl-names = "iddig_irq_init\0drvvbus_init\0drvvbus_low\0drvvbus_high";
			pinctrl-0 = <0x23>;
			pinctrl-1 = <0x24>;
			pinctrl-2 = <0x25>;
			pinctrl-3 = <0x26>;
			status = "okay";
		};

		sound@11220000 {
			compatible = "mediatek,mt8127-soc-machine";
			reg = <0x00 0x11220000 0x00 0x1000 0x00 0x11221000 0x00 0x4000>;
			interrupts = <0x00 0x68 0x08>;
			clocks = <0x05 0x03 0x06 0x4e 0x06 0x4d 0x06 0x56 0x06 0x3a 0x06 0x3b 0x06 0x3c 0x06 0x3d 0x06 0x3e 0x27>;
			clock-names = "infra_sys_audio_clk\0top_audio_sel\0top_audintbus_sel\0top_apll_sel\0top_audpll\0top_audpll_d4\0top_audpll_d8\0top_audpll_d16\0top_audpll_d24\0clk26m";
		};

		mediatek,mt8127-soc-dl1-pcm@11220000 {
			compatible = "mediatek,mt8127-soc-dl1-pcm";
		};

		mediatek,mt8127-soc-dl1-awb-pcm@11220000 {
			compatible = "mediatek,mt8127-soc-dl1-awb-pcm";
		};

		mediatek,mt8127-soc-dummy-codec@11220000 {
			compatible = "mediatek,mt8127-soc-dummy-codec";
		};

		mediatek,mt8127-soc-codec@11220000 {
			compatible = "mediatek,mt8127-soc-codec";
		};

		mediatek,Routing-Control@11220000 {
			compatible = "mediatek,Routing-Control";
		};

		mediatek,mt8127-soc-dai-driver@11220000 {
			compatible = "mediatek,mt8127-soc-dai-driver";
		};

		mediatek,mt8127-soc-voip-bt-in@11220000 {
			compatible = "mediatek,mt8127-soc-voip-bt-in";
		};

		mediatek,mt8127-soc-ul1-pcm@11220000 {
			compatible = "mediatek,mt8127-soc-ul1-pcm";
		};

		mediatek,mt8127-soc-voip-bt-out@11220000 {
			compatible = "mediatek,mt8127-soc-voip-bt-out";
		};

		mediatek,mt8127-soc-i2s0-pcm@11220000 {
			compatible = "mediatek,mt8127-soc-i2s0-pcm";
		};

		mediatek,mt8127-soc-i2s0dl1-pcm@11220000 {
			compatible = "mediatek,mt8127-soc-i2s0dl1-pcm";
		};

		mediatek,mt8127-soc-dummy-pcm@11220000 {
			compatible = "mediatek,mt8127-soc-dummy-pcm";
		};

		mediatek,mt8127-soc-fm-i2s-pcm@11220000 {
			compatible = "mediatek,mt8127-soc-fm-i2s-pcm";
		};

		mediatek,mt8127-soc-fm-i2s-awb-pcm@11220000 {
			compatible = "mediatek,mt8127-soc-fm-i2s-awb-pcm";
		};

		mediatek,mt8127-soc-hdmi-pcm@11220000 {
			compatible = "mediatek,mt8127-soc-hdmi-pcm";
		};

		mediatek,mt8127-soc-i2s0awb-pcm@11220000 {
			compatible = "mediatek,mt8127-soc-i2s0awb-pcm";
		};

		mediatek,mt8127-soc-routing-pcm@11220000 {
			compatible = "mediatek,mt8127-soc-routing-pcm";
		};

		mediatek,mt8127-soc-uldlloopback-pcm@11220000 {
			compatible = "mediatek,mt8127-soc-uldlloopback-pcm";
		};

		mmc@11230000 {
			compatible = "mediatek,mt8127-mmc";
			reg = <0x00 0x11230000 0x00 0x1000>;
			interrupts = <0x00 0x27 0x08>;
			clocks = <0x08 0x0e 0x28>;
			clock-names = "source\0hclk";
			status = "okay";
			pinctrl-names = "default\0state_uhs";
			pinctrl-0 = <0x29>;
			pinctrl-1 = <0x2a>;
			bus-width = <0x08>;
			max-frequency = <0xbebc200>;
			cap-mmc-highspeed;
			mmc-hs200-1_8v;
			vmmc-supply = <0x2b>;
			vqmmc-supply = <0x2c>;
			cmd_int_delay = <0x08>;
			write_int_delay = <0x08>;
			host_function = <0x00>;
			host_id = <0x00>;
			boot = <0x01>;
			non-removable;
		};

		mmc@11240000 {
			compatible = "mediatek,mt8127-mmc";
			reg = <0x00 0x11240000 0x00 0x1000>;
			interrupts = <0x00 0x28 0x08>;
			clocks = <0x08 0x0f 0x28>;
			clock-names = "source\0hclk";
			status = "okay";
			pinctrl-names = "default\0state_uhs";
			pinctrl-0 = <0x2d>;
			pinctrl-1 = <0x2e>;
			bus-width = <0x04>;
			max-frequency = <0xbebc200>;
			cap-sd-highspeed;
			sd-uhs-sdr50;
			sd-uhs-sdr104;
			cd-gpios = <0x07 0x18 0x00>;
			vmmc-supply = <0x2f>;
			vqmmc-supply = <0x30>;
			host_function = <0x01>;
			host_id = <0x01>;
			boot = <0x00>;
		};

		mmc@11250000 {
			compatible = "mediatek,mt8127-mmc";
			reg = <0x00 0x11240000 0x00 0x1000>;
			interrupts = <0x00 0x29 0x08>;
			clocks = <0x08 0x10 0x28>;
			clock-names = "source\0hclk";
			status = "disabled";
		};

		mfg@13000000 {
			compatible = "mediatek,mt8127-mfg";
			#address-cells = <0x01>;
			#size-cells = <0x01>;
			reg = <0x00 0x13000000 0x00 0x1000>;
			power-domains = <0x31 0x01>;
		};

		mali@13040000 {
			compatible = "arm,mali-450\0arm,mali-utgard";
			reg = <0x00 0x13040000 0x00 0x30000>;
			interrupts = <0x00 0xaa 0x08 0x00 0xab 0x08 0x00 0xac 0x08 0x00 0xad 0x08 0x00 0xae 0x08 0x00 0xaf 0x08 0x00 0xb0 0x08 0x00 0xb1 0x08 0x00 0xb2 0x08 0x00 0xb3 0x08 0x00 0xb4 0x08>;
			interrupt-names = "IRQGP\0IRQGPMMU\0IRQPP0\0IRQPPMMU0\0IRQPP1\0IRQPPMMU1\0IRQPP2\0IRQPPMMU2\0IRQPP3\0IRQPPMMU3\0IRQPP";
			clocks = <0x32 0x01 0x06 0x27 0x06 0x19 0x06 0x46>;
			clock-names = "mm_smi\0mfg_pll\0mfg_pll_univ\0mfg_sel";
			power-domains = <0x31 0x02>;
		};

		syscon@14000000 {
			#address-cells = <0x01>;
			#size-cells = <0x01>;
			compatible = "mediatek,mt8127-mmsys\0syscon";
			reg = <0x00 0x14000000 0x00 0x1000>;
			#clock-cells = <0x01>;
			power-domains = <0x31 0x01>;
			linux,phandle = <0x32>;
			phandle = <0x32>;
		};

		larb@14010000 {
			compatible = "mediatek,mt8127-smi-larb";
			reg = <0x00 0x14010000 0x00 0x1000>;
			mediatek,smi = <0x33>;
			mediatek,larbid = <0x00>;
			clocks = <0x32 0x02 0x32 0x02>;
			clock-names = "apb\0smi";
			power-domains = <0x31 0x01>;
		};

		smi@14011000 {
			compatible = "mediatek,mt8127-smi";
			reg = <0x00 0x14011000 0x00 0x1000>;
			clocks = <0x05 0x02 0x32 0x01>;
			clock-names = "apb\0smi";
			power-domains = <0x31 0x01>;
			linux,phandle = <0x33>;
			phandle = <0x33>;
		};

		mdp@14001000 {
			compatible = "mediatek,mt8127-mdp-rdma";
			reg = <0x00 0x14001000 0x00 0x1000>;
			clocks = <0x32 0x0f 0x32 0x11 0x34 0x02 0x34 0x03>;
			clock-names = "clk_mdp_rdma\0clk_cam_mdp\0clk_img_cam_smi\0clk_img_cam_cam";
		};

		mdp@14002000 {
			compatible = "mediatek,mt8127-mdp-rsz0";
			reg = <0x00 0x14002000 0x00 0x1000>;
			clocks = <0x32 0x0e>;
			clock-names = "clk_mdp_rsz0";
		};

		mdp@14003000 {
			compatible = "mediatek,mt8127-mdp-rsz1";
			reg = <0x00 0x14003000 0x00 0x1000>;
			clocks = <0x32 0x0d>;
			clock-names = "clk_mdp_rsz1";
		};

		mdp@14004000 {
			compatible = "mediatek,mt8127-mdp-wdma";
			reg = <0x00 0x14004000 0x00 0x1000>;
			clocks = <0x32 0x0c 0x34 0x04 0x34 0x05 0x34 0x01>;
			clock-names = "clk_mdp_wdma\0clk_img_sen_tg\0clk_img_sen_cam\0clk_img_larb2_smi";
		};

		mdp@14005000 {
			compatible = "mediatek,mt8127-mdp-wrot";
			reg = <0x00 0x14005000 0x00 0x1000>;
			clocks = <0x32 0x0b>;
			clock-names = "clk_mdp_wrot";
		};

		mdp@14006000 {
			compatible = "mediatek,mt8127-mdp-tdshp";
			reg = <0x00 0x14006000 0x00 0x1000>;
			clocks = <0x32 0x0a>;
			clock-names = "clk_mdp_tdshp";
		};

		dispsys@14007000 {
			compatible = "mediatek,mt8127-disp-ovl";
			reg = <0x00 0x14007000 0x00 0x1000>;
			interrupts = <0x00 0x99 0x08>;
			clocks = <0x32 0x09>;
			clock-names = "clk_disp_ovl";
		};

		dispsys@14008000 {
			compatible = "mediatek,mt8127-disp-rdma0";
			reg = <0x00 0x14008000 0x00 0x1000>;
			interrupts = <0x00 0x98 0x08>;
			clocks = <0x32 0x08>;
			clock-names = "clk_disp_rdma0";
		};

		dispsys@14009000 {
			compatible = "mediatek,mt8127-disp-wdma";
			reg = <0x00 0x14009000 0x00 0x1000>;
			interrupts = <0x00 0x9a 0x08>;
			clocks = <0x32 0x07>;
			clock-names = "clk_disp_wdma";
		};

		dispsys@1400a000 {
			compatible = "mediatek,mt8127-disp-bls";
			reg = <0x00 0x1400a000 0x00 0x1000>;
			interrupts = <0x00 0x9b 0x08>;
			clocks = <0x32 0x06 0x32 0x10 0x27 0x06 0x48>;
			clock-names = "clk_disp_bls\0clk_disp_bls_26m\0clk26m\0pwm_sel";
		};

		dispsys@1400b000 {
			compatible = "mediatek,mt8127-disp-color";
			reg = <0x00 0x1400b000 0x00 0x1000>;
			interrupts = <0x00 0x9c 0x08>;
			clocks = <0x32 0x05>;
			clock-names = "clk_disp_color";
		};

		dispsys@1400c000 {
			compatible = "mediatek,mt8127-disp-dsi";
			reg = <0x00 0x1400c000 0x00 0x1000>;
			interrupts = <0x00 0x9d 0x08>;
			clocks = <0x32 0x16 0x32 0x17>;
			clock-names = "clk_dsi_engine\0clk_dsi_dig";
		};

		dispsys@1400d000 {
			compatible = "mediatek,mt8127-disp-dpi0";
			reg = <0x00 0x1400d000 0x00 0x1000>;
			interrupts = <0x00 0x9e 0x08>;
			clocks = <0x32 0x18 0x32 0x19>;
			clock-names = "clk_dpi_digl\0clk_dpi_engine";
		};

		dispsys@1400e000 {
			compatible = "mediatek,mt8127-mm-mutex";
			reg = <0x00 0x1400e000 0x00 0x1000>;
			interrupts = <0x00 0xa1 0x08>;
			clocks = <0x32 0x13 0x32 0x04>;
			clock-names = "clk_mm_mutex_32k\0clk_mm_mutex";
		};

		dispsys@1400f000 {
			compatible = "mediatek,mt8127-mm-cmdq";
			reg = <0x00 0x1400f000 0x00 0x1000>;
			interrupts = <0x00 0x9f 0x08 0x00 0xa0 0x08>;
			clocks = <0x32 0x03>;
			clock-names = "clk_mm_cmdq";
		};

		met_smi@14011000 {
			compatible = "mediatek,met_smi";
			reg = <0x00 0x14011000 0x00 0x1000 0x00 0x14010000 0x00 0x1000 0x00 0x16010000 0x00 0x1000 0x00 0x15001000 0x00 0x1000>;
			clocks = <0x32 0x01 0x32 0x02 0x35 0x02 0x34 0x01>;
			clock-names = "smi-common\0smi-larb0\0vdec-larb1\0img-larb2";
		};

		dispsys@14012000 {
			compatible = "mediatek,mt8127-disp-rdma1";
			reg = <0x00 0x14012000 0x00 0x1000>;
			interrupts = <0x00 0xa4 0x08>;
			clocks = <0x32 0x14>;
			clock-names = "clk_disp_rdma1";
		};

		dispsys@14013000 {
			compatible = "mediatek,mt8127-disp-ufoe";
			reg = <0x00 0x14013000 0x00 0x1000>;
			clocks = <0x32 0x15>;
			clock-names = "clk_disp_ufoe";
		};

		dispsys@14014000 {
			compatible = "mediatek,mt8127-disp-dpi1";
			reg = <0x00 0x14014000 0x00 0x1000>;
			clocks = <0x32 0x1a 0x32 0x1b>;
			clock-names = "clk_dpi1_digl\0clk_dpi1_engine";
		};

		dispsys@14015000 {
			compatible = "mediatek,mt8127-disp-hdmi";
			power-domains = <0x31 0x01>;
			reg = <0x00 0x14015000 0x00 0x1000 0x00 0x11013000 0x00 0x1000 0x00 0x10012000 0x00 0x1000>;
			interrupts = <0x00 0xb6 0x08>;
			clocks = <0x05 0x0b 0x08 0x1a 0x32 0x1e 0x32 0x1f 0x32 0x20 0x32 0x21>;
			clock-names = "clk_cec_pdn\0clk_ddc_pdn\0clk_hdmi_pixel\0clk_hdmi_pll\0clk_hdmi_audio\0clk_hdmi_spdif";
			status = "okay";
			pinctrl-names = "default\0hdmi_hpd";
			pinctrl-0 = <0x36>;
			pinctrl-1 = <0x37>;
			hdmi_power_control = <0x07 0x1b 0x00>;
		};

		dispsys@14016000 {
			compatible = "mediatek,mt8127-disp-lvds";
			reg = <0x00 0x14016000 0x00 0x1000>;
			clocks = <0x32 0x22 0x32 0x23>;
			clock-names = "clk_lvds_pixel\0clk_lvds_cts";
		};

		dispsys@14017000 {
			compatible = "mediatek,mt8127-disp-tve";
			reg = <0x00 0x14017000 0x00 0x1000>;
			clocks = <0x32 0x1c 0x32 0x1d>;
			clock-names = "clk_tve_output\0clk_tve_input";
		};

		accdet@ {
			compatible = "mediatek,mt8127-accdet";
			status = "okay";
			interrupt-parent = <0x07>;
			interrupts = <0x04 0x08>;
			eint-debounce = <0x100>;
			accdet-gpio = <0x07 0x1a 0x00>;
			accdet-mic-vol = <0x07>;
			headset-mode-setting = <0x900 0x400 0x01 0x3f0 0x800 0x800 0x20>;
			accdet-plugout-debounce = <0x14>;
			accdet-mic-mode = <0x01>;
			headset-three-key-threshold = <0x00 0x50 0xdc 0x1f4>;
			headset-four-key-threshold = <0x00 0x3a 0x79 0xc0 0x1c2>;
			pinctrl-names = "default\0state_eint_as_int";
			pinctrl-0 = <0x38>;
			pinctrl-1 = <0x39>;
		};

		touch@ {
			compatible = "mediatek,mt8127-touch";
			vtouch-supply = <0x3a>;
			interrupt-parent = <0x07>;
			interrupts = <0x2e 0x02>;
			debounce = <0x00>;
			int-gpio = <0x07 0x23 0x00>;
			rst-gpio = <0x07 0x2d 0x00>;
			tpd-resolution = <0x320 0x500>;
			use-tpd-button = <0x00>;
			tpd-key-num = <0x03>;
			tpd-key-local = <0x8b 0xac 0x9e 0x00>;
			tpd-key-dim-local = <0x5a 0x373 0x64 0x28 0xe6 0x373 0x64 0x28 0x172 0x373 0x64 0x28 0x00 0x00 0x00 0x00>;
			tpd-max-touch-num = <0x05>;
			tpd-filter-enable = <0x01>;
			tpd-filter-pixel-density = <0x5d>;
			tpd-filter-custom-prameters = <0x00 0x00 0x00 0x00 0x00 0x00 0x00 0x00 0x00 0x00 0x00 0x00>;
			tpd-filter-custom-speed = <0x00 0x00 0x00>;
			pinctrl-names = "default\0state_eint_as_int\0state_eint_output0\0state_eint_output1\0state_rst_output0\0state_rst_output1";
			pinctrl-0 = <0x3b>;
			pinctrl-1 = <0x3c>;
			pinctrl-2 = <0x3d>;
			pinctrl-3 = <0x3e>;
			pinctrl-4 = <0x3f>;
			pinctrl-5 = <0x40>;
			status = "okay";
		};

		fb@80000000 {
			compatible = "mediatek,mt8127-fb";
		};

		lcm {
			compatible = "mediatek,lcm";
			reg-lcm-supply = <0x41>;
			lcm_power_gpio = <0x07 0x53 0x00>;
			lcm_bias_en_gpio = <0x07 0x20 0x00>;
			lcm_power_en_gpio = <0x07 0x12 0x00>;
			lcm_reset_gpio = <0x07 0x53 0x00>;
		};

		lcm2 {
			compatible = "mediatek,lcm2";
			reg-lcm-supply = <0x41>;
			lcm_power_gpio = <0x07 0x53 0x00>;
			lcm_bias_en_gpio = <0x07 0x20 0x00>;
			lcm_power_en_gpio = <0x07 0x12 0x00>;
			lcm_reset_gpio = <0x07 0x53 0x00>;
		};

		syscon@15000000 {
			#address-cells = <0x01>;
			#size-cells = <0x01>;
			compatible = "mediatek,mt8127-imgsys\0syscon";
			reg = <0x00 0x15000000 0x00 0x1000>;
			#clock-cells = <0x01>;
			power-domains = <0x31 0x04>;
			linux,phandle = <0x34>;
			phandle = <0x34>;
		};

		ispsys@15000000 {
			compatible = "mediatek,mt8127-ispsys";
			reg = <0x00 0x15004000 0x00 0x9000 0x00 0x15000000 0x00 0x10000 0x00 0x10010000 0x00 0x1000>;
			interrupts = <0x00 0x8f 0x08 0x00 0x90 0x08 0x00 0x91 0x08>;
			clocks = <0x34 0x02 0x34 0x03 0x34 0x04 0x34 0x05 0x06 0x45 0x06 0x1b 0x06 0x1f>;
			clock-names = "IMG_CAM_SMI\0IMG_CAM_CAM\0IMG_SEN_TG\0IMG_SEN_CAM\0TOP_CAMTG_SEL\0TOP_UNIVPLL_D26\0TOP_UNIVPLL2_D2";
		};

		larb@15001000 {
			compatible = "mediatek,mt8127-smi-larb";
			reg = <0x00 0x15001000 0x00 0x1000>;
			mediatek,smi = <0x33>;
			mediatek,larbid = <0x02>;
			clocks = <0x34 0x01 0x34 0x01>;
			clock-names = "apb\0smi";
			power-domains = <0x31 0x04>;
		};

		camera1@15008000 {
			compatible = "mediatek,mt8127-camera_hw";
			reg = <0x00 0x15008000 0x00 0x1000>;
			reg-vcama-supply = <0x42>;
			reg-vcamd-supply = <0x43>;
			reg-vcamio-supply = <0x44>;
			reg-vcamaf-supply = <0x45>;
			pinctrl-names = "default\0cam0_rst0\0cam0_rst1\0cam0_pnd0\0cam0_pnd1\0cam1_rst0\0cam1_rst1\0cam1_pnd0\0cam1_pnd1\0mclk_cfg\0mclk_gpio";
			pinctrl-0 = <0x46>;
			pinctrl-1 = <0x47>;
			pinctrl-2 = <0x48>;
			pinctrl-3 = <0x49>;
			pinctrl-4 = <0x4a>;
			pinctrl-5 = <0x4b>;
			pinctrl-6 = <0x4c>;
			pinctrl-7 = <0x4d>;
			pinctrl-8 = <0x4e>;
			pinctrl-9 = <0x4f>;
			pinctrl-10 = <0x50>;
			status = "okay";
		};

		camera2@15008000 {
			compatible = "mediatek,mt8127-camera_hw2";
			reg = <0x00 0x15008000 0x00 0x1000>;
		};

		venc@15009000 {
			compatible = "mediatek,mt8127-venc";
			reg = <0x00 0x15009000 0x00 0x1000>;
			interrupts = <0x00 0x8c 0x08>;
			clocks = <0x34 0x06>;
			clock-names = "venc";
		};

		jpgenc@1500a000 {
			compatible = "mediatek,mt8127-jpgenc\0mediatek,jpgenc";
			reg = <0x00 0x1500a000 0x00 0x1000>;
			interrupts = <0x00 0x8d 0x08>;
			clocks = <0x34 0x06>;
			clock-names = "venc-jpgenc";
		};

		syscon@16000000 {
			#address-cells = <0x01>;
			#size-cells = <0x01>;
			compatible = "mediatek,mt8127-vdecsys\0syscon";
			reg = <0x00 0x16000000 0x00 0x1000>;
			#clock-cells = <0x01>;
			power-domains = <0x31 0x03>;
			clocks = <0x06 0x41>;
			clock-names = "mm_sel";
			linux,phandle = <0x35>;
			phandle = <0x35>;
		};

		larb@16010000 {
			compatible = "mediatek,mt8127-smi-larb";
			reg = <0x00 0x16010000 0x00 0x1000>;
			mediatek,smi = <0x33>;
			mediatek,larbid = <0x01>;
			clocks = <0x35 0x01 0x35 0x02>;
			clock-names = "apb\0smi";
			power-domains = <0x31 0x03>;
		};

		VDEC@16020000 {
			compatible = "mediatek,mt8127-vdec";
			reg = <0x00 0x16020000 0x00 0x10000>;
			interrupts = <0x00 0x8b 0x08>;
		};

		btcvsd@18000000 {
			compatible = "mediatek,mt8127-audio_bt_cvsd\0mediatek,audio_bt_cvsd";
			offset = <0xf00 0x800 0xfd0 0xfd4 0xfd8>;
			reg = <0x00 0x10001000 0x00 0x1000 0x00 0x18000000 0x00 0x10000 0x00 0x18080000 0x00 0x8000>;
			interrupts = <0x00 0xba 0x08>;
		};

		consys@18070000 {
			compatible = "mediatek,mt8127-consys";
			reg = <0x00 0x18070000 0x00 0x200 0x00 0x10001000 0x00 0x1000>;
			clocks = <0x05 0x07>;
			clock-names = "bus";
			power-domains = <0x31 0x00>;
			interrupts = <0x00 0xb9 0x08 0x00 0xa3 0x08>;
			resets = <0x51 0x0c>;
			reset-names = "connsys";
			status = "okay";
			pinctrl-names = "default\0gps_lna_state_init\0gps_lna_state_oh\0gps_lna_state_ol";
			pinctrl-0 = <0x52>;
			pinctrl-1 = <0x53>;
			pinctrl-2 = <0x54>;
			pinctrl-3 = <0x55>;
			vcn18-supply = <0x56>;
			vcn28-supply = <0x57>;
			vcn33_bt-supply = <0x58>;
			vcn33_wifi-supply = <0x59>;
		};

		wifi@180f0000 {
			compatible = "mediatek,wifi";
			reg = <0x00 0x180f0000 0x00 0x5c>;
			interrupts = <0x00 0xb8 0x08>;
			clocks = <0x08 0x0d>;
			clock-names = "wifi-dma";
		};

		bat_meter {
			compatible = "mediatek,bat_meter";
			r_bat_sense = <0x04>;
			r_i_sense = <0x04>;
			r_charger_1 = <0x14a>;
			r_charger_2 = <0x27>;
			temperature_t0 = <0x6e>;
			temperature_t1 = <0x00>;
			temperature_t2 = <0x19>;
			temperature_t3 = <0x32>;
			temperature_t = <0xff>;
			fg_meter_resistance = <0x00>;
			q_max_pos_50 = <0x9fb>;
			q_max_pos_25 = <0x9fb>;
			q_max_pos_0 = <0x9fb>;
			q_max_neg_10 = <0x9fb>;
			q_max_pos_50_h_current = <0x926>;
			q_max_pos_25_h_current = <0x926>;
			q_max_pos_0_h_current = <0x926>;
			q_max_neg_10_h_current = <0x926>;
			oam_d5 = <0x00>;
			change_tracking_point = <0x01>;
			cust_tracking_point = <0x0e>;
			cust_r_sense = <0x38>;
			cust_hw_cc = <0x00>;
			aging_tuning_value = <0x64>;
			cust_r_fg_offset = <0x17>;
			ocv_board_compesate = <0x00>;
			r_fg_board_base = <0x3e8>;
			r_fg_board_slope = <0x3e8>;
			car_tune_value = <0x59>;
			current_detect_r_fg = <0xffffffff>;
			minerroroffset = <0x3e8>;
			fg_vbat_average_size = <0x12>;
			r_fg_value = <0x14>;
			cust_poweron_delta_capacity_tolrance = <0x28>;
			cust_poweron_low_capacity_tolrance = <0x05>;
			cust_poweron_max_vbat_tolrance = <0x5a>;
			cust_poweron_delta_vbat_tolrance = <0x03>;
			cust_poweron_delta_hw_sw_ocv_capacity_tolrance = <0x0a>;
			fixed_tbat_25 = <0x00>;
			vbat_normal_wakeup = <0xe10>;
			vbat_low_power_wakeup = <0xdac>;
			normal_wakeup_period = <0xc8>;
			low_power_wakeup_period = <0x12c>;
			close_poweroff_wakeup_period = <0x1e>;
			rbat_pull_up_r = <0x4204>;
			rbat_pull_down_r = <0x7530>;
			rbat_pull_up_volt = <0x708>;
			batt_temperature_table_num = <0x11>;
			batt_temperature_table = <0xffffffec 0x10a8d 0xfffffff1 0xd192 0xfffffff6 0xa60a 0xfffffffb 0x8464 0x00 0x6a53 0x05 0x5605 0x0a 0x4606 0x0f 0x3952 0x14 0x2f31 0x19 0x2710 0x1e 0x207b 0x23 0x1b24 0x28 0x16ca 0x2d 0x1335 0x32 0x1041 0x37 0xdcf 0x3c 0xbc6>;
			battery_profile_t0_num = <0x34>;
			battery_profile_t0 = <0x00 0x1046 0x02 0x101d 0x04 0xffe 0x06 0xfe4 0x08 0xfcc 0x0b 0xfb4 0x0d 0xf9d 0x0f 0xf88 0x11 0xf77 0x13 0xf64 0x15 0xf51 0x17 0xf40 0x19 0xf2f 0x1b 0xf1f 0x1e 0xf11 0x20 0xf03 0x22 0xef7 0x24 0xeec 0x26 0xee5 0x28 0xee1 0x2a 0xedb 0x2c 0xecc 0x2e 0xebb 0x30 0xeaa 0x33 0xe98 0x35 0xe86 0x37 0xe75 0x39 0xe65 0x3b 0xe58 0x3d 0xe4c 0x3f 0xe42 0x41 0xe39 0x43 0xe31 0x46 0xe29 0x48 0xe22 0x4a 0xe19 0x4c 0xe10 0x4e 0xe05 0x50 0xdf8 0x52 0xdea 0x54 0xddc 0x56 0xdcd 0x59 0xdb8 0x5b 0xda4 0x5d 0xd8d 0x5f 0xd80 0x61 0xd73 0x63 0xd62 0x64 0xd39 0x64 0xd20 0x64 0xd11 0x64 0xd11>;
			battery_profile_t1_num = <0x34>;
			battery_profile_t1 = <0x00 0x1046 0x02 0x101d 0x04 0xffe 0x06 0xfe4 0x08 0xfcc 0x0b 0xfb4 0x0d 0xf9d 0x0f 0xf88 0x11 0xf77 0x13 0xf64 0x15 0xf51 0x17 0xf40 0x19 0xf2f 0x1b 0xf1f 0x1e 0xf11 0x20 0xf03 0x22 0xef7 0x24 0xeec 0x26 0xee5 0x28 0xee1 0x2a 0xedb 0x2c 0xecc 0x2e 0xebb 0x30 0xeaa 0x33 0xe98 0x35 0xe86 0x37 0xe75 0x39 0xe65 0x3b 0xe58 0x3d 0xe4c 0x3f 0xe42 0x41 0xe39 0x43 0xe31 0x46 0xe29 0x48 0xe22 0x4a 0xe19 0x4c 0xe10 0x4e 0xe05 0x50 0xdf8 0x52 0xdea 0x54 0xddc 0x56 0xdcd 0x59 0xdb8 0x5b 0xda4 0x5d 0xd8d 0x5f 0xd80 0x61 0xd73 0x63 0xd62 0x64 0xd39 0x64 0xd20 0x64 0xd11 0x64 0xd11>;
			battery_profile_t2_num = <0x34>;
			battery_profile_t2 = <0x00 0x1046 0x02 0x101d 0x04 0xffe 0x06 0xfe4 0x08 0xfcc 0x0b 0xfb4 0x0d 0xf9d 0x0f 0xf88 0x11 0xf77 0x13 0xf64 0x15 0xf51 0x17 0xf40 0x19 0xf2f 0x1b 0xf1f 0x1e 0xf11 0x20 0xf03 0x22 0xef7 0x24 0xeec 0x26 0xee5 0x28 0xee1 0x2a 0xedb 0x2c 0xecc 0x2e 0xebb 0x30 0xeaa 0x33 0xe98 0x35 0xe86 0x37 0xe75 0x39 0xe65 0x3b 0xe58 0x3d 0xe4c 0x3f 0xe42 0x41 0xe39 0x43 0xe31 0x46 0xe29 0x48 0xe22 0x4a 0xe19 0x4c 0xe10 0x4e 0xe05 0x50 0xdf8 0x52 0xdea 0x54 0xddc 0x56 0xdcd 0x59 0xdb8 0x5b 0xda4 0x5d 0xd8d 0x5f 0xd80 0x61 0xd73 0x63 0xd62 0x64 0xd39 0x64 0xd20 0x64 0xd11 0x64 0xd11>;
			battery_profile_t3_num = <0x34>;
			battery_profile_t3 = <0x00 0x1046 0x02 0x101d 0x04 0xffe 0x06 0xfe4 0x08 0xfcc 0x0b 0xfb4 0x0d 0xf9d 0x0f 0xf88 0x11 0xf77 0x13 0xf64 0x15 0xf51 0x17 0xf40 0x19 0xf2f 0x1b 0xf1f 0x1e 0xf11 0x20 0xf03 0x22 0xef7 0x24 0xeec 0x26 0xee5 0x28 0xee1 0x2a 0xedb 0x2c 0xecc 0x2e 0xebb 0x30 0xeaa 0x33 0xe98 0x35 0xe86 0x37 0xe75 0x39 0xe65 0x3b 0xe58 0x3d 0xe4c 0x3f 0xe42 0x41 0xe39 0x43 0xe31 0x46 0xe29 0x48 0xe22 0x4a 0xe19 0x4c 0xe10 0x4e 0xe05 0x50 0xdf8 0x52 0xdea 0x54 0xddc 0x56 0xdcd 0x59 0xdb8 0x5b 0xda4 0x5d 0xd8d 0x5f 0xd80 0x61 0xd73 0x63 0xd62 0x64 0xd39 0x64 0xd20 0x64 0xd11 0x64 0xd11>;
			r_profile_t0_num = <0x34>;
			r_profile_t0 = <0x78 0x1046 0x78 0x101d 0x78 0xffe 0x7a 0xfe4 0x7a 0xfcc 0x7a 0xfb4 0x7b 0xf9d 0x7f 0xf88 0x84 0xf77 0x84 0xf64 0x84 0xf51 0x89 0xf40 0x8a 0xf2f 0x8e 0xf1f 0x93 0xf11 0x98 0xf03 0x9d 0xef7 0xa2 0xeec 0xa8 0xee5 0xaf 0xee1 0xaf 0xedb 0xa0 0xecc 0x94 0xebb 0x8a 0xeaa 0x84 0xe98 0x7d 0xe86 0x7b 0xe75 0x7a 0xe65 0x7b 0xe58 0x7b 0xe4c 0x7d 0xe42 0x7f 0xe39 0x82 0xe31 0x82 0xe29 0x84 0xe22 0x84 0xe19 0x84 0xe10 0x82 0xe05 0x80 0xdf8 0x7f 0xdea 0x80 0xddc 0x84 0xdcd 0x84 0xdb8 0x87 0xda4 0x85 0xd8d 0x91 0xd80 0xa7 0xd73 0xe6 0xd62 0x134 0xd39 0x10c 0xd20 0xf3 0xd11 0xf5 0xd11>;
			r_profile_t1_num = <0x34>;
			r_profile_t1 = <0x78 0x1046 0x78 0x101d 0x78 0xffe 0x7a 0xfe4 0x7a 0xfcc 0x7a 0xfb4 0x7b 0xf9d 0x7f 0xf88 0x84 0xf77 0x84 0xf64 0x84 0xf51 0x89 0xf40 0x8a 0xf2f 0x8e 0xf1f 0x93 0xf11 0x98 0xf03 0x9d 0xef7 0xa2 0xeec 0xa8 0xee5 0xaf 0xee1 0xaf 0xedb 0xa0 0xecc 0x94 0xebb 0x8a 0xeaa 0x84 0xe98 0x7d 0xe86 0x7b 0xe75 0x7a 0xe65 0x7b 0xe58 0x7b 0xe4c 0x7d 0xe42 0x7f 0xe39 0x82 0xe31 0x82 0xe29 0x84 0xe22 0x84 0xe19 0x84 0xe10 0x82 0xe05 0x80 0xdf8 0x7f 0xdea 0x80 0xddc 0x84 0xdcd 0x84 0xdb8 0x87 0xda4 0x85 0xd8d 0x91 0xd80 0xa7 0xd73 0xe6 0xd62 0x134 0xd39 0x10c 0xd20 0xf3 0xd11 0xf5 0xd11>;
			r_profile_t2_num = <0x34>;
			r_profile_t2 = <0x78 0x1046 0x78 0x101d 0x78 0xffe 0x7a 0xfe4 0x7a 0xfcc 0x7a 0xfb4 0x7b 0xf9d 0x7f 0xf88 0x84 0xf77 0x84 0xf64 0x84 0xf51 0x89 0xf40 0x8a 0xf2f 0x8e 0xf1f 0x93 0xf11 0x98 0xf03 0x9d 0xef7 0xa2 0xeec 0xa8 0xee5 0xaf 0xee1 0xaf 0xedb 0xa0 0xecc 0x94 0xebb 0x8a 0xeaa 0x84 0xe98 0x7d 0xe86 0x7b 0xe75 0x7a 0xe65 0x7b 0xe58 0x7b 0xe4c 0x7d 0xe42 0x7f 0xe39 0x82 0xe31 0x82 0xe29 0x84 0xe22 0x84 0xe19 0x84 0xe10 0x82 0xe05 0x80 0xdf8 0x7f 0xdea 0x80 0xddc 0x84 0xdcd 0x84 0xdb8 0x87 0xda4 0x85 0xd8d 0x91 0xd80 0xa7 0xd73 0xe6 0xd62 0x134 0xd39 0x10c 0xd20 0xf3 0xd11 0xf5 0xd11>;
			r_profile_t3_num = <0x34>;
			r_profile_t3 = <0x78 0x1046 0x78 0x101d 0x78 0xffe 0x7a 0xfe4 0x7a 0xfcc 0x7a 0xfb4 0x7b 0xf9d 0x7f 0xf88 0x84 0xf77 0x84 0xf64 0x84 0xf51 0x89 0xf40 0x8a 0xf2f 0x8e 0xf1f 0x93 0xf11 0x98 0xf03 0x9d 0xef7 0xa2 0xeec 0xa8 0xee5 0xaf 0xee1 0xaf 0xedb 0xa0 0xecc 0x94 0xebb 0x8a 0xeaa 0x84 0xe98 0x7d 0xe86 0x7b 0xe75 0x7a 0xe65 0x7b 0xe58 0x7b 0xe4c 0x7d 0xe42 0x7f 0xe39 0x82 0xe31 0x82 0xe29 0x84 0xe22 0x84 0xe19 0x84 0xe10 0x82 0xe05 0x80 0xdf8 0x7f 0xdea 0x80 0xddc 0x84 0xdcd 0x84 0xdb8 0x87 0xda4 0x85 0xd8d 0x91 0xd80 0xa7 0xd73 0xe6 0xd62 0x134 0xd39 0x10c 0xd20 0xf3 0xd11 0xf5 0xd11>;
		};

		BAT_NOTIFY {
			compatible = "mediatek,bat_notify";
		};

		bat_comm {
			compatible = "mediatek,battery";
			pinctrl-names = "default\0bq24157s_cd0\0bq24157s_cd1\0bq24157s_stat0\0bq24157s_stat1\0bq24157s_otg0\0bq24157s_otg1\0gpio_set_33\0gpio_set_37\0gpio_set_21";
			pinctrl-0 = <0x5a>;
			pinctrl-1 = <0x5b>;
			pinctrl-2 = <0x5c>;
			pinctrl-3 = <0x5d>;
			pinctrl-4 = <0x5e>;
			pinctrl-5 = <0x5f>;
			pinctrl-6 = <0x60>;
			pinctrl-7 = <0x61>;
			pinctrl-8 = <0x62>;
			pinctrl-9 = <0x63>;
			status = "okay";
			stop_charging_in_takling = <0x01>;
			talking_recharge_voltage = <0xed8>;
			talking_sync_time = <0x3c>;
			mtk_temperature_recharge_support = <0x01>;
			max_charge_temperature = <0x32>;
			max_charge_temperature_minus_x_degree = <0x2f>;
			min_charge_temperature = <0x00>;
			min_charge_temperature_plus_x_degree = <0x06>;
			err_charge_temperature = <0xff>;
			v_pre2cc_thres = <0xd48>;
			v_cc2topoff_thres = <0xfd2>;
			recharging_voltage = <0xff0>;
			charging_full_current = <0xf8>;
			config_usb_if = <0x00>;
			usb_charger_current_suspend = <0x00>;
			usb_charger_current_unconfigured = <0x1b58>;
			usb_charger_current_configured = <0xc350>;
			usb_charger_current = <0xc350>;
			ac_charger_input_current = <0x186a0>;
			ac_charger_current = <0x15f90>;
			non_std_ac_charger_current = <0xc350>;
			charging_host_charger_current = <0xfde8>;
			apple_0_5a_charger_current = <0xc350>;
			apple_1_0a_charger_current = <0xfde8>;
			apple_2_1a_charger_current = <0x13880>;
			bat_low_temp_protect_enable = <0x00>;
			v_charger_enable = <0x00>;
			v_charger_max = <0x1964>;
			v_charger_min = <0x1130>;
			onehundred_percent_tracking_time = <0x0a>;
			npercent_tracking_time = <0x14>;
			sync_to_real_tracking_time = <0x3c>;
			v_0percent_tracking = <0xd48>;
			high_battery_voltage_support = <0x00>;
			mtk_jeita_standard_support = <0x00>;
			cust_soc_jeita_sync_time = <0x1e>;
			jeita_recharge_voltage = <0x100e>;
			jeita_temp_above_pos_60_cv_voltage = <0x3e8fa0>;
			jeita_temp_pos_45_to_pos_60_cv_voltage = <0x3e8fa0>;
			jeita_temp_pos_10_to_pos_45_cv_voltage = <0x401640>;
			jeita_temp_pos_0_to_pos_10_cv_voltage = <0x3e8fa0>;
			jeita_temp_neg_10_to_pos_0_cv_voltage = <0x3b8260>;
			jeita_temp_below_neg_10_cv_voltage = <0x3b8260>;
			jeita_neg_10_to_pos_0_full_current = <0x78>;
			jeita_temp_pos_45_to_pos_60_recharge_voltage = <0xfa0>;
			jeita_temp_pos_10_to_pos_45_recharge_voltage = <0x1004>;
			jeita_temp_pos_0_to_pos_10_recharge_voltage = <0xfa0>;
			jeita_temp_neg_10_to_pos_0_recharge_voltage = <0xed8>;
			jeita_temp_pos_45_to_pos_60_cc2topoff_threshold = <0xfd2>;
			jeita_temp_pos_10_to_pos_45_cc2topoff_threshold = <0xfd2>;
			jeita_temp_pos_0_to_pos_10_cc2topoff_threshold = <0xfd2>;
			jeita_temp_neg_10_to_pos_0_cc2topoff_threshold = <0xf0a>;
		};

		gpio_id@0 {
			compatible = "mediatek,gpio-id";
			gpio_id_33 = <0x07 0x21 0x00>;
			gpio_id_37 = <0x07 0x25 0x00>;
			gpio_id_21 = <0x07 0x15 0x00>;
			status = "okay";
		};

		dcm {
			compatible = "mediatek,mt8127-dcm";
			reg = <0x00 0x10000000 0x00 0x1000 0x00 0x10001000 0x00 0x1000 0x00 0x10003000 0x00 0x1000 0x00 0x10004000 0x00 0x1000 0x00 0x10006000 0x00 0x1000 0x00 0x1000c000 0x00 0x1000 0x00 0x1000d000 0x00 0x1000 0x00 0x10200000 0x00 0x1000 0x00 0x10205000 0x00 0x1000 0x00 0x10208000 0x00 0x1000 0x00 0x11007000 0x00 0x1000 0x00 0x11008000 0x00 0x1000 0x00 0x11009000 0x00 0x1000 0x00 0x11200000 0x00 0x1000 0x00 0x11230000 0x00 0x1000 0x00 0x11240000 0x00 0x1000 0x00 0x11250000 0x00 0x1000 0x00 0x13000000 0x00 0x1000 0x00 0x14000000 0x00 0x1000 0x00 0x14010000 0x00 0x1000 0x00 0x14011300 0x00 0x1000 0x00 0x15001000 0x00 0x1000 0x00 0x15004000 0x00 0x1000 0x00 0x1500a000 0x00 0x1000 0x00 0x15009000 0x00 0x1000 0x00 0x16000000 0x00 0x1000 0x00 0x16010000 0x00 0x1000>;
			clocks = <0x06 0x41 0x08 0x0b>;
			clock-names = "mm_sel\0usb0_main";
		};

		dumchar {
			compatible = "mediatek,mt8127-dummy_char";
			status = "disabled";
		};

		flashlight {
			compatible = "mediatek,camera_flashlight";
			pinctrl-names = "default\0enable_high\0enable_low";
			pinctrl-0 = <0x52>;
			pinctrl-1 = <0x64>;
			pinctrl-2 = <0x65>;
			status = "okay";
		};

		led@0 {
			compatible = "mediatek,red";
			led_mode = <0x02>;
			data;
			pwm_config = <0x00 0x00 0x00 0x00 0x00>;
		};

		led@1 {
			compatible = "mediatek,green";
			led_mode = <0x03>;
			data = <0x09>;
			pwm_config = <0x00 0x00 0x00 0x00 0x00>;
		};

		led@2 {
			compatible = "mediatek,blue";
			led_mode = <0x03>;
			data = <0x08>;
			pwm_config = <0x00 0x00 0x00 0x00 0x00>;
		};

		led@3 {
			compatible = "mediatek,jogball-backlight";
			led_mode = <0x00>;
			data;
			pwm_config = <0x00 0x00 0x00 0x00 0x00>;
		};

		led@4 {
			compatible = "mediatek,keyboard-backlight";
			led_mode = <0x00>;
			data;
			pwm_config = <0x00 0x00 0x00 0x00 0x00>;
		};

		led@5 {
			compatible = "mediatek,button-backlight";
			led_mode = <0x03>;
			data = <0x00>;
			pwm_config = <0x00 0x00 0x00 0x00 0x00>;
		};

		led@6 {
			compatible = "mediatek,lcd-backlight";
			led_mode = <0x05>;
			data;
			pwm_config = <0x00 0x00 0x00 0x00 0x00>;
			gpios = <0x07 0x2b 0x00>;
		};

		isp_pipemgr {
			compatible = "mediatek,mt8127-isp_pipemgr";
		};

		isp_sysram {
			compatible = "mediatek,mt8127-isp_sysram";
		};

		mtee {
			compatible = "mediatek,mtee";
			clocks = <0x05 0x08 0x08 0x21>;
			clock-names = "TRNG\0GCPU";
		};
	};

	bring-up {
		compatible = "mediatek,clk-bring-up";
		clocks = <0x06 0x44 0x06 0x43 0x06 0x42 0x06 0x5b 0x06 0x41 0x05 0x01 0x08 0x12>;
		clock-names = "0\01\02\03\04\05\06";
	};

	cust_accel@0 {
		compatible = "mediatek,mxc400x";
		i2c_num = <0x02>;
		i2c_addr = <0x15 0x00 0x00 0x00>;
		direction = <0x00>;
		power_id = <0xffff>;
		power_vol = <0x00>;
		firlen = <0x00>;
		is_batch_supported = <0x00>;
	};

	cust_alsps@0 {
		compatible = "mediatek,apds9930";
		i2c_num = <0x02>;
		i2c_addr = <0x72 0x48 0x78 0x00>;
		polling_mode_ps = <0x00>;
		polling_mode_als = <0x01>;
		power_id = <0xffff>;
		power_vol = <0x00>;
		als_level = <0x05 0x0a 0x19 0x32 0x64 0x96 0xc8 0x190 0x3e8 0x5dc 0x7d0 0xbb8 0x1388 0x1f40 0x2710>;
		als_value = <0x0a 0x32 0x64 0x96 0xc8 0xfa 0x118 0x118 0x640 0x640 0x640 0x1770 0x1770 0x2328 0x2800 0x2800>;
		ps_threshold_high = <0x78>;
		ps_threshold_low = <0x64>;
		is_batch_supported_ps = <0x00>;
		is_batch_supported_als = <0x00>;
	};

	cust_gyro@0 {
		compatible = "mediatek,mpu6050gy";
		i2c_num = <0x02>;
		i2c_addr = <0x68 0x00 0x00 0x00>;
		direction = <0x07>;
		power_id = <0xffff>;
		power_vol = <0x00>;
		firlen = <0x00>;
		is_batch_supported = <0x00>;
	};

	cust_mag@0 {
		compatible = "mediatek,akm09911";
		i2c_num = <0x02>;
		i2c_addr = <0x0d 0x00 0x00 0x00>;
		direction = <0x07>;
		power_id = <0xffff>;
		power_vol = <0x00>;
		is_batch_supported = <0x00>;
	};

	mtcpufreq {
		compatible = "mediatek,mt8127-cpufreq";
		reg-vproc-supply = <0x66>;
	};

	vibrator@0 {
		compatible = "mediatek,vibrator";
		vib_timer = <0x19>;
		vib_limit = <0x09>;
		vib_vol = <0x05>;
	};
};
